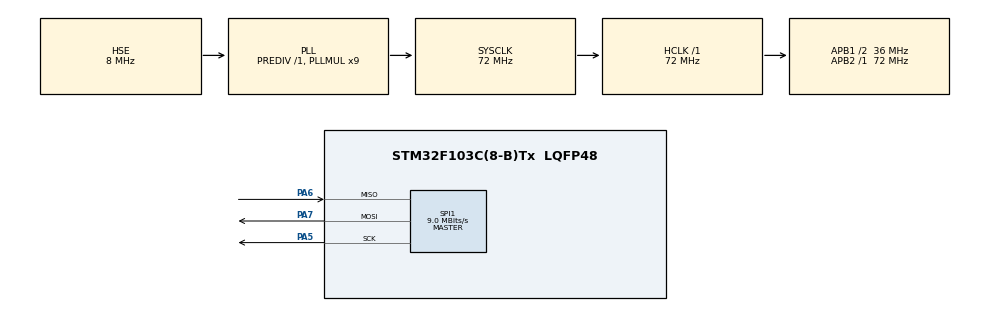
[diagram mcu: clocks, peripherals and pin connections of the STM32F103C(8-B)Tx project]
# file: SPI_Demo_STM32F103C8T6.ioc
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Mcu.Family=STM32F1
Mcu.Name=STM32F103C(8-B)Tx
Mcu.Package=LQFP48
NVIC.PriorityGroup=NVIC_PRIORITYGROUP_4
PA13.Mode=Serial_Wire
PA13.Signal=SYS_JTMS-SWDIO
PA14.Mode=Serial_Wire
PA14.Signal=SYS_JTCK-SWCLK
PA5.Mode=Full_Duplex_Master
PA5.Signal=SPI1_SCK
PA6.Mode=Full_Duplex_Master
PA6.Signal=SPI1_MISO
PA7.Mode=Full_Duplex_Master
PA7.Signal=SPI1_MOSI
PD0-OSC_IN.Mode=HSE-External-Oscillator
PD0-OSC_IN.Signal=RCC_OSC_IN
PD1-OSC_OUT.Mode=HSE-External-Oscillator
PD1-OSC_OUT.Signal=RCC_OSC_OUT
ProjectManager.HeapSize=0x200
ProjectManager.StackSize=0x400
ProjectManager.TargetToolchain=Makefile
RCC.AHBFreq_Value=72000000
RCC.APB1CLKDivider=RCC_HCLK_DIV2
RCC.APB1Freq_Value=36000000
RCC.APB1TimFreq_Value=72000000
RCC.APB2Freq_Value=72000000
RCC.APB2TimFreq_Value=72000000
RCC.HCLKFreq_Value=72000000
RCC.PLLMUL=RCC_PLL_MUL9
RCC.PLLSourceVirtual=RCC_PLLSOURCE_HSE
RCC.SYSCLKFreq_VALUE=72000000
RCC.SYSCLKSource=RCC_SYSCLKSOURCE_PLLCLK
RCC.USBFreq_Value=72000000
SPI1.BaudRatePrescaler=SPI_BAUDRATEPRESCALER_8
SPI1.CalculateBaudRate=9.0 MBits/s
SPI1.Direction=SPI_DIRECTION_2LINES
SPI1.Mode=SPI_MODE_MASTER
SPI1.VirtualType=VM_MASTER
board=custom

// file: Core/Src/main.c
/* USER CODE BEGIN Header */
/**
  ******************************************************************************
  * @file           : main.c
  * @brief          : Main program body
  ******************************************************************************
  * @attention
  *
  * <h2><center>&copy; Copyright (c) 2025 STMicroelectronics.
  * All rights reserved.</center></h2>
  *
  * This software component is licensed by ST under BSD 3-Clause license,
  * the "License"; You may not use this file except in compliance with the
  * License. You may obtain a copy of the License at:
  *                        opensource.org/licenses/BSD-3-Clause
  *
  ******************************************************************************
  */
/* USER CODE END Header */
#include "main.h"
#include "spi.h"
#include "gpio.h"

/* USER CODE BEGIN Includes */
#include "Graphic/fast_setup/fast_setup.h"
#include "Graphic/sim_app/simple_text.h"

#include "SPI_Common/soft_spi/soft_spi.h"
#include "SPI_Common/hard_spi/hard_spi.h"
#include "WX25Q64/wx25q64.h"
#include <stdio.h>

/* USER CODE END Includes */

void SystemClock_Config(void);

/* USER CODE BEGIN 0 */

SOFTSPI_Protocol  spi;
HARDSPI_Protocol  hard_spi;
CommonSPIHandle   spi_handle;
WX25Q64_Handle    wx25q64;

SPI_GPIOPack ss = {GPIOA, GPIO_PIN_4};
SPI_GPIOPack clk = {GPIOA, GPIO_PIN_5};
SPI_GPIOPack mosi = {GPIOA, GPIO_PIN_7};
SPI_GPIOPack miso = {GPIOA, GPIO_PIN_6};
void init_wx25q64()
{
    SPI_Configure config;
    config.delay_time = HAL_MAX_DELAY;

    init_softspi_protocol(
      &spi, ss, clk, mosi, miso, config
    );
    register_softspi_spihandle(
      &spi_handle, &spi
    );

    // init_hardspi_protocol(
    //   &hard_spi, &hspi1, ss, config
    // );
    // register_hardspi_spihandle(&spi_handle, &hard_spi);

    WX25Q64_Handle_register_spi_handle(
      &wx25q64, &spi_handle
    );
}

/* USER CODE END 0 */

int main(void)
{

  /* MCU Configuration--------------------------------------------------------*/

  /* Reset of all peripherals, Initializes the Flash interface and the Systick. */
  HAL_Init();

  /* Configure the system clock */
  SystemClock_Config();

  /* Initialize all configured peripherals */
  MX_GPIO_Init();
  MX_SPI1_Init();
  /* USER CODE BEGIN 2 */
  CCDeviceHandler handler;
  CCGraphicTextEdit edit;

  oled_soft_iic_setup(&handler);
  init_wx25q64();
  char buffers[50];
  // uint32_t device_id = 0;
  // wx25q64.op->WX25Q64_Fetch_Property(&wx25q64, &device_id, ID);
  // uint8_t mid = GET_MID(device_id);
  // uint16_t did = GET_DID(device_id);
  // snprintf(buffers, 20, "Manu   ID: %X", mid);
  // set_simple_text(&edit, &handler, buffers);
  // snprintf(buffers, 20, "Device ID: %X", did);
  // set_newline_text(&edit, &handler, buffers);

  uint8_t array[] = "2345";
  uint8_t fetch[5] = {0, 0, 0, 0, 0};
  wx25q64.op->write_data(&wx25q64, 0x000000, array, 4);
  wx25q64.op->read_data(&wx25q64, 0x000000, fetch, 4);
  set_simple_text(&edit, &handler, "Read from raw:");
  snprintf(buffers, 50,
      "%X,%X,%X,%X",
      fetch[0], fetch[1], fetch[2], fetch[3]);
  set_newline_text(&edit, &handler, buffers);
  /* USER CODE END 2 */

  /* Infinite loop */
  while (1)
  {

  }
}

void SystemClock_Config(void)
{
  RCC_OscInitTypeDef RCC_OscInitStruct = {0};
  RCC_ClkInitTypeDef RCC_ClkInitStruct = {0};

  /** Initializes the RCC Oscillators according to the specified parameters
  * in the RCC_OscInitTypeDef structure.
  */
  RCC_OscInitStruct.OscillatorType = RCC_OSCILLATORTYPE_HSE;
  RCC_OscInitStruct.HSEState = RCC_HSE_ON;
  RCC_OscInitStruct.HSEPredivValue = RCC_HSE_PREDIV_DIV1;
  RCC_OscInitStruct.HSIState = RCC_HSI_ON;
  RCC_OscInitStruct.PLL.PLLState = RCC_PLL_ON;
  RCC_OscInitStruct.PLL.PLLSource = RCC_PLLSOURCE_HSE;
  RCC_OscInitStruct.PLL.PLLMUL = RCC_PLL_MUL9;
  if (HAL_RCC_OscConfig(&RCC_OscInitStruct) != HAL_OK)
  {
    Error_Handler();
  }
  /** Initializes the CPU, AHB and APB buses clocks
  */
  RCC_ClkInitStruct.ClockType = RCC_CLOCKTYPE_HCLK|RCC_CLOCKTYPE_SYSCLK
                              |RCC_CLOCKTYPE_PCLK1|RCC_CLOCKTYPE_PCLK2;
  RCC_ClkInitStruct.SYSCLKSource = RCC_SYSCLKSOURCE_PLLCLK;
  RCC_ClkInitStruct.AHBCLKDivider = RCC_SYSCLK_DIV1;
  RCC_ClkInitStruct.APB1CLKDivider = RCC_HCLK_DIV2;
  RCC_ClkInitStruct.APB2CLKDivider = RCC_HCLK_DIV1;

  if (HAL_RCC_ClockConfig(&RCC_ClkInitStruct, FLASH_LATENCY_2) != HAL_OK)
  {
    Error_Handler();
  }
}

void Error_Handler(void)
{
  __disable_irq();
  while (1)
  {
  }
}

/************************ (C) COPYRIGHT STMicroelectronics *****END OF FILE****/
